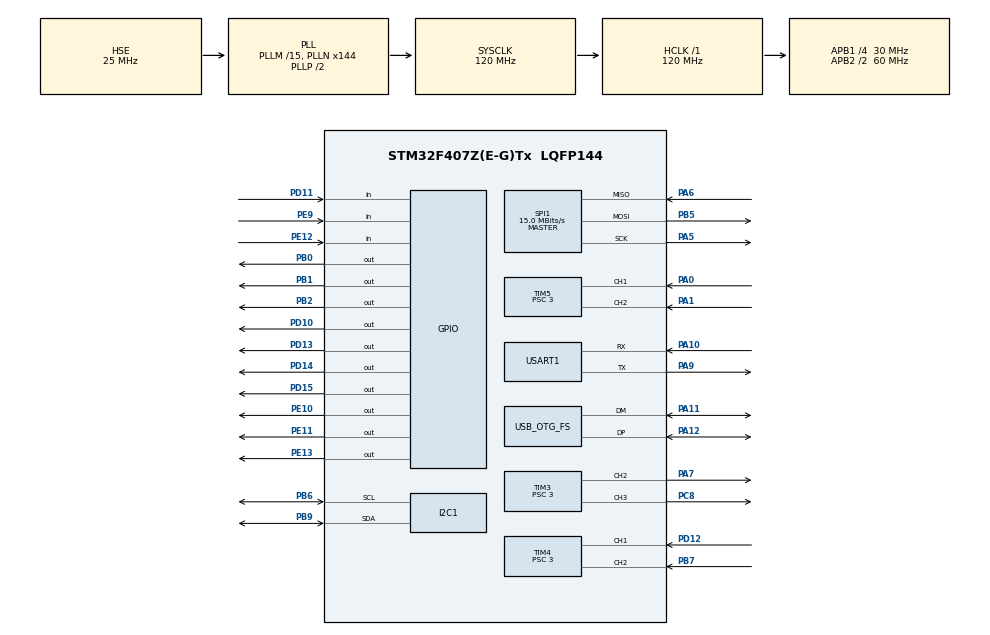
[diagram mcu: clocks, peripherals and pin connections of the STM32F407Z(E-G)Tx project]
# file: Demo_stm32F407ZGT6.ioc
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FREERTOS.MEMORY_ALLOCATION=2
FREERTOS.Tasks01=defaultTask,0,2000,StartDefaultTask,Default,NULL,Dynamic,NULL,NULL
FREERTOS.configMINIMAL_STACK_SIZE=2000
FREERTOS.configTICK_RATE_HZ=100
FREERTOS.configTOTAL_HEAP_SIZE=55360
Mcu.Family=STM32F4
Mcu.Name=STM32F407Z(E-G)Tx
Mcu.Package=LQFP144
NVIC.OTG_FS_IRQn=true\:5\:0\:false\:false\:true\:true\:false\:true
NVIC.PriorityGroup=NVIC_PRIORITYGROUP_4
NVIC.TIM1_UP_TIM10_IRQn=true\:0\:0\:false\:false\:true\:false\:false\:true
NVIC.TIM2_IRQn=true\:5\:0\:false\:false\:true\:true\:true\:true
NVIC.TimeBase=TIM1_UP_TIM10_IRQn
NVIC.TimeBaseIP=TIM1
PA0-WKUP.Signal=S_TIM5_CH1
PA1.Signal=S_TIM5_CH2
PA10.Mode=Asynchronous
PA10.Signal=USART1_RX
PA11.Mode=Device_Only
PA11.Signal=USB_OTG_FS_DM
PA12.Mode=Device_Only
PA12.Signal=USB_OTG_FS_DP
PA5.Mode=Full_Duplex_Master
PA5.Signal=SPI1_SCK
PA6.Mode=Full_Duplex_Master
PA6.Signal=SPI1_MISO
PA7.Signal=S_TIM3_CH2
PA9.Mode=Asynchronous
PA9.Signal=USART1_TX
PB0.Signal=GPIO_Output
PB1.Signal=GPIO_Output
PB2.Signal=GPIO_Output
PB5.Mode=Full_Duplex_Master
PB5.Signal=SPI1_MOSI
PB6.Mode=I2C
PB6.Signal=I2C1_SCL
PB7.Signal=S_TIM4_CH2
PB9.Mode=I2C
PB9.Signal=I2C1_SDA
PC8.Signal=S_TIM3_CH3
PD10.Signal=GPIO_Output
PD11.Signal=GPIO_Input
PD12.Signal=S_TIM4_CH1
PD13.Signal=GPIO_Output
PD14.Signal=GPIO_Output
PD15.Signal=GPIO_Output
PE10.Signal=GPIO_Output
PE11.Signal=GPIO_Output
PE12.Signal=GPIO_Input
PE13.Signal=GPIO_Output
PE9.Signal=GPIO_Input
PH0-OSC_IN.Mode=HSE-External-Oscillator
PH0-OSC_IN.Signal=RCC_OSC_IN
PH1-OSC_OUT.Mode=HSE-External-Oscillator
PH1-OSC_OUT.Signal=RCC_OSC_OUT
ProjectManager.HeapSize=0x200
ProjectManager.StackSize=0x400
ProjectManager.TargetToolchain=STM32CubeIDE
RCC.48MHZClocksFreq_Value=48000000
RCC.AHBFreq_Value=120000000
RCC.APB1CLKDivider=RCC_HCLK_DIV4
RCC.APB1Freq_Value=30000000
RCC.APB1TimFreq_Value=60000000
RCC.APB2CLKDivider=RCC_HCLK_DIV2
RCC.APB2Freq_Value=60000000
RCC.APB2TimFreq_Value=120000000
RCC.CortexFreq_Value=120000000
RCC.HCLKFreq_Value=120000000
RCC.HSE_VALUE=25000000
RCC.HSI_VALUE=16000000
RCC.LSE_VALUE=32768
RCC.PLLM=15
RCC.PLLN=144
RCC.PLLQ=5
RCC.SYSCLKFreq_VALUE=120000000
RCC.SYSCLKSource=RCC_SYSCLKSOURCE_PLLCLK
RCC.VCOOutputFreq_Value=240000000
SH.S_TIM3_CH2.0=TIM3_CH2,PWM Generation2 CH2
SH.S_TIM3_CH3.0=TIM3_CH3,PWM Generation3 CH3
SH.S_TIM4_CH1.0=TIM4_CH1,Encoder_Interface
SH.S_TIM4_CH2.0=TIM4_CH2,Encoder_Interface
SH.S_TIM5_CH1.0=TIM5_CH1,Encoder_Interface
SH.S_TIM5_CH2.0=TIM5_CH2,Encoder_Interface
SPI1.BaudRatePrescaler=SPI_BAUDRATEPRESCALER_4
SPI1.CalculateBaudRate=15.0 MBits/s
SPI1.Direction=SPI_DIRECTION_2LINES
SPI1.Mode=SPI_MODE_MASTER
SPI1.VirtualType=VM_MASTER
TIM2.AutoReloadPreload=TIM_AUTORELOAD_PRELOAD_ENABLE
TIM2.Period=83
TIM2.Prescaler=999
TIM3.AutoReloadPreload=TIM_AUTORELOAD_PRELOAD_ENABLE
TIM3.Channel-PWM\ Generation2\ CH2=TIM_CHANNEL_2
TIM3.Channel-PWM\ Generation3\ CH3=TIM_CHANNEL_3
TIM3.Period=2099
TIM3.Prescaler=3
TIM4.EncoderMode=TIM_ENCODERMODE_TI12
TIM4.Period=0xffff
TIM4.Prescaler=3
TIM5.EncoderMode=TIM_ENCODERMODE_TI12
TIM5.Period=0xffff
TIM5.Prescaler=3
USART1.VirtualMode=VM_ASYNC
USB_DEVICE.CLASS_NAME_FS=DFU
USB_DEVICE.VirtualMode-DFU_FS=Dfu
USB_DEVICE.VirtualModeFS=Dfu_FS
USB_OTG_FS.VirtualMode=Device_Only
VP_FREERTOS_VS_CMSIS_V1.Mode=CMSIS_V1
VP_SYS_VS_tim1.Mode=TIM1
VP_TIM2_VS_ClockSourceINT.Mode=Internal
VP_TIM3_VS_ClockSourceINT.Mode=Internal
VP_USB_DEVICE_VS_USB_DEVICE_DFU_FS.Mode=DFU_FS
board=custom

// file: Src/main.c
/* USER CODE BEGIN Header */
/**
  ******************************************************************************
  * @file           : main.c
  * @brief          : Main program body
  ******************************************************************************
  * @attention
  *
  * <h2><center>&copy; Copyright (c) 2020 STMicroelectronics.
  * All rights reserved.</center></h2>
  *
  * This software component is licensed by ST under Ultimate Liberty license
  * SLA0044, the "License"; You may not use this file except in compliance with
  * the License. You may obtain a copy of the License at:
  *                             www.st.com/SLA0044
  *
  ******************************************************************************
  */
/* USER CODE END Header */

#include "main.h"
#include "cmsis_os.h"
#include "usb_device.h"

/* USER CODE BEGIN Includes */
#include "pa_Main/pa_Main.h"
/* USER CODE END Includes */

I2C_HandleTypeDef hi2c1;

SPI_HandleTypeDef hspi1;

TIM_HandleTypeDef htim2;
TIM_HandleTypeDef htim3;
TIM_HandleTypeDef htim4;
TIM_HandleTypeDef htim5;

UART_HandleTypeDef huart1;

osThreadId defaultTaskHandle;

void SystemClock_Config(void);
static void MX_GPIO_Init(void);
static void MX_I2C1_Init(void);
static void MX_SPI1_Init(void);
static void MX_TIM2_Init(void);
static void MX_TIM3_Init(void);
static void MX_TIM4_Init(void);
static void MX_TIM5_Init(void);
static void MX_USART1_UART_Init(void);
void StartDefaultTask(void const * argument);

int main(void)
{

  /* MCU Configuration--------------------------------------------------------*/

  /* Reset of all peripherals, Initializes the Flash interface and the Systick. */
  HAL_Init();

  /* Configure the system clock */
  SystemClock_Config();

  /* Initialize all configured peripherals */
  MX_GPIO_Init();
  MX_I2C1_Init();
  MX_SPI1_Init();
  MX_TIM2_Init();
  MX_TIM3_Init();
  MX_TIM4_Init();
  MX_TIM5_Init();
  MX_USART1_UART_Init();

  /* Create the thread(s) */
  /* definition and creation of defaultTask */
  osThreadDef(defaultTask, StartDefaultTask, osPriorityNormal, 0, 2000);
  defaultTaskHandle = osThreadCreate(osThread(defaultTask), NULL);

  /* Start scheduler */
  osKernelStart();

  /* We should never get here as control is now taken by the scheduler */

  /* Infinite loop */
  while (1)
  {

  }
}

void SystemClock_Config(void)
{
  RCC_OscInitTypeDef RCC_OscInitStruct = {0};
  RCC_ClkInitTypeDef RCC_ClkInitStruct = {0};

  /** Configure the main internal regulator output voltage
  */
  __HAL_RCC_PWR_CLK_ENABLE();
  __HAL_PWR_VOLTAGESCALING_CONFIG(PWR_REGULATOR_VOLTAGE_SCALE1);
  /** Initializes the CPU, AHB and APB busses clocks
  */
  RCC_OscInitStruct.OscillatorType = RCC_OSCILLATORTYPE_HSE;
  RCC_OscInitStruct.HSEState = RCC_HSE_ON;
  RCC_OscInitStruct.PLL.PLLState = RCC_PLL_ON;
  RCC_OscInitStruct.PLL.PLLSource = RCC_PLLSOURCE_HSE;
  RCC_OscInitStruct.PLL.PLLM = 15;
  RCC_OscInitStruct.PLL.PLLN = 144;
  RCC_OscInitStruct.PLL.PLLP = RCC_PLLP_DIV2;
  RCC_OscInitStruct.PLL.PLLQ = 5;
  if (HAL_RCC_OscConfig(&RCC_OscInitStruct) != HAL_OK)
  {
    Error_Handler();
  }
  /** Initializes the CPU, AHB and APB busses clocks
  */
  RCC_ClkInitStruct.ClockType = RCC_CLOCKTYPE_HCLK|RCC_CLOCKTYPE_SYSCLK
                              |RCC_CLOCKTYPE_PCLK1|RCC_CLOCKTYPE_PCLK2;
  RCC_ClkInitStruct.SYSCLKSource = RCC_SYSCLKSOURCE_PLLCLK;
  RCC_ClkInitStruct.AHBCLKDivider = RCC_SYSCLK_DIV1;
  RCC_ClkInitStruct.APB1CLKDivider = RCC_HCLK_DIV4;
  RCC_ClkInitStruct.APB2CLKDivider = RCC_HCLK_DIV2;

  if (HAL_RCC_ClockConfig(&RCC_ClkInitStruct, FLASH_LATENCY_3) != HAL_OK)
  {
    Error_Handler();
  }
}

static void MX_I2C1_Init(void)
{

  hi2c1.Instance = I2C1;
  hi2c1.Init.ClockSpeed = 100000;
  hi2c1.Init.DutyCycle = I2C_DUTYCYCLE_2;
  hi2c1.Init.OwnAddress1 = 0;
  hi2c1.Init.AddressingMode = I2C_ADDRESSINGMODE_7BIT;
  hi2c1.Init.DualAddressMode = I2C_DUALADDRESS_DISABLE;
  hi2c1.Init.OwnAddress2 = 0;
  hi2c1.Init.GeneralCallMode = I2C_GENERALCALL_DISABLE;
  hi2c1.Init.NoStretchMode = I2C_NOSTRETCH_DISABLE;
  if (HAL_I2C_Init(&hi2c1) != HAL_OK)
  {
    Error_Handler();
  }

}

static void MX_SPI1_Init(void)
{

  /* SPI1 parameter configuration*/
  hspi1.Instance = SPI1;
  hspi1.Init.Mode = SPI_MODE_MASTER;
  hspi1.Init.Direction = SPI_DIRECTION_2LINES;
  hspi1.Init.DataSize = SPI_DATASIZE_8BIT;
  hspi1.Init.CLKPolarity = SPI_POLARITY_LOW;
  hspi1.Init.CLKPhase = SPI_PHASE_1EDGE;
  hspi1.Init.NSS = SPI_NSS_SOFT;
  hspi1.Init.BaudRatePrescaler = SPI_BAUDRATEPRESCALER_4;
  hspi1.Init.FirstBit = SPI_FIRSTBIT_MSB;
  hspi1.Init.TIMode = SPI_TIMODE_DISABLE;
  hspi1.Init.CRCCalculation = SPI_CRCCALCULATION_DISABLE;
  hspi1.Init.CRCPolynomial = 10;
  if (HAL_SPI_Init(&hspi1) != HAL_OK)
  {
    Error_Handler();
  }

}

static void MX_TIM2_Init(void)
{

  TIM_ClockConfigTypeDef sClockSourceConfig = {0};
  TIM_MasterConfigTypeDef sMasterConfig = {0};

  htim2.Instance = TIM2;
  htim2.Init.Prescaler = 999;
  htim2.Init.CounterMode = TIM_COUNTERMODE_UP;
  htim2.Init.Period = 83;
  htim2.Init.ClockDivision = TIM_CLOCKDIVISION_DIV1;
  htim2.Init.AutoReloadPreload = TIM_AUTORELOAD_PRELOAD_ENABLE;
  if (HAL_TIM_Base_Init(&htim2) != HAL_OK)
  {
    Error_Handler();
  }
  sClockSourceConfig.ClockSource = TIM_CLOCKSOURCE_INTERNAL;
  if (HAL_TIM_ConfigClockSource(&htim2, &sClockSourceConfig) != HAL_OK)
  {
    Error_Handler();
  }
  sMasterConfig.MasterOutputTrigger = TIM_TRGO_RESET;
  sMasterConfig.MasterSlaveMode = TIM_MASTERSLAVEMODE_DISABLE;
  if (HAL_TIMEx_MasterConfigSynchronization(&htim2, &sMasterConfig) != HAL_OK)
  {
    Error_Handler();
  }

}

static void MX_TIM3_Init(void)
{

  TIM_ClockConfigTypeDef sClockSourceConfig = {0};
  TIM_MasterConfigTypeDef sMasterConfig = {0};
  TIM_OC_InitTypeDef sConfigOC = {0};

  htim3.Instance = TIM3;
  htim3.Init.Prescaler = 3;
  htim3.Init.CounterMode = TIM_COUNTERMODE_UP;
  htim3.Init.Period = 2099;
  htim3.Init.ClockDivision = TIM_CLOCKDIVISION_DIV1;
  htim3.Init.AutoReloadPreload = TIM_AUTORELOAD_PRELOAD_ENABLE;
  if (HAL_TIM_Base_Init(&htim3) != HAL_OK)
  {
    Error_Handler();
  }
  sClockSourceConfig.ClockSource = TIM_CLOCKSOURCE_INTERNAL;
  if (HAL_TIM_ConfigClockSource(&htim3, &sClockSourceConfig) != HAL_OK)
  {
    Error_Handler();
  }
  if (HAL_TIM_PWM_Init(&htim3) != HAL_OK)
  {
    Error_Handler();
  }
  sMasterConfig.MasterOutputTrigger = TIM_TRGO_RESET;
  sMasterConfig.MasterSlaveMode = TIM_MASTERSLAVEMODE_DISABLE;
  if (HAL_TIMEx_MasterConfigSynchronization(&htim3, &sMasterConfig) != HAL_OK)
  {
    Error_Handler();
  }
  sConfigOC.OCMode = TIM_OCMODE_PWM1;
  sConfigOC.Pulse = 0;
  sConfigOC.OCPolarity = TIM_OCPOLARITY_HIGH;
  sConfigOC.OCFastMode = TIM_OCFAST_DISABLE;
  if (HAL_TIM_PWM_ConfigChannel(&htim3, &sConfigOC, TIM_CHANNEL_2) != HAL_OK)
  {
    Error_Handler();
  }
  if (HAL_TIM_PWM_ConfigChannel(&htim3, &sConfigOC, TIM_CHANNEL_3) != HAL_OK)
  {
    Error_Handler();
  }
  HAL_TIM_MspPostInit(&htim3);

}

static void MX_TIM4_Init(void)
{

  TIM_Encoder_InitTypeDef sConfig = {0};
  TIM_MasterConfigTypeDef sMasterConfig = {0};

  htim4.Instance = TIM4;
  htim4.Init.Prescaler = 3;
  htim4.Init.CounterMode = TIM_COUNTERMODE_UP;
  htim4.Init.Period = 0xffff;
  htim4.Init.ClockDivision = TIM_CLOCKDIVISION_DIV1;
  htim4.Init.AutoReloadPreload = TIM_AUTORELOAD_PRELOAD_DISABLE;
  sConfig.EncoderMode = TIM_ENCODERMODE_TI12;
  sConfig.IC1Polarity = TIM_ICPOLARITY_RISING;
  sConfig.IC1Selection = TIM_ICSELECTION_DIRECTTI;
  sConfig.IC1Prescaler = TIM_ICPSC_DIV1;
  sConfig.IC1Filter = 0;
  sConfig.IC2Polarity = TIM_ICPOLARITY_RISING;
  sConfig.IC2Selection = TIM_ICSELECTION_DIRECTTI;
  sConfig.IC2Prescaler = TIM_ICPSC_DIV1;
  sConfig.IC2Filter = 0;
  if (HAL_TIM_Encoder_Init(&htim4, &sConfig) != HAL_OK)
  {
    Error_Handler();
  }
  sMasterConfig.MasterOutputTrigger = TIM_TRGO_RESET;
  sMasterConfig.MasterSlaveMode = TIM_MASTERSLAVEMODE_DISABLE;
  if (HAL_TIMEx_MasterConfigSynchronization(&htim4, &sMasterConfig) != HAL_OK)
  {
    Error_Handler();
  }

}

static void MX_TIM5_Init(void)
{

  TIM_Encoder_InitTypeDef sConfig = {0};
  TIM_MasterConfigTypeDef sMasterConfig = {0};

  htim5.Instance = TIM5;
  htim5.Init.Prescaler = 3;
  htim5.Init.CounterMode = TIM_COUNTERMODE_UP;
  htim5.Init.Period = 0xffff;
  htim5.Init.ClockDivision = TIM_CLOCKDIVISION_DIV1;
  htim5.Init.AutoReloadPreload = TIM_AUTORELOAD_PRELOAD_DISABLE;
  sConfig.EncoderMode = TIM_ENCODERMODE_TI12;
  sConfig.IC1Polarity = TIM_ICPOLARITY_RISING;
  sConfig.IC1Selection = TIM_ICSELECTION_DIRECTTI;
  sConfig.IC1Prescaler = TIM_ICPSC_DIV1;
  sConfig.IC1Filter = 0;
  sConfig.IC2Polarity = TIM_ICPOLARITY_RISING;
  sConfig.IC2Selection = TIM_ICSELECTION_DIRECTTI;
  sConfig.IC2Prescaler = TIM_ICPSC_DIV1;
  sConfig.IC2Filter = 0;
  if (HAL_TIM_Encoder_Init(&htim5, &sConfig) != HAL_OK)
  {
    Error_Handler();
  }
  sMasterConfig.MasterOutputTrigger = TIM_TRGO_RESET;
  sMasterConfig.MasterSlaveMode = TIM_MASTERSLAVEMODE_DISABLE;
  if (HAL_TIMEx_MasterConfigSynchronization(&htim5, &sMasterConfig) != HAL_OK)
  {
    Error_Handler();
  }

}

static void MX_USART1_UART_Init(void)
{

  huart1.Instance = USART1;
  huart1.Init.BaudRate = 115200;
  huart1.Init.WordLength = UART_WORDLENGTH_8B;
  huart1.Init.StopBits = UART_STOPBITS_1;
  huart1.Init.Parity = UART_PARITY_NONE;
  huart1.Init.Mode = UART_MODE_TX_RX;
  huart1.Init.HwFlowCtl = UART_HWCONTROL_NONE;
  huart1.Init.OverSampling = UART_OVERSAMPLING_16;
  if (HAL_UART_Init(&huart1) != HAL_OK)
  {
    Error_Handler();
  }

}

static void MX_GPIO_Init(void)
{
  GPIO_InitTypeDef GPIO_InitStruct = {0};

  /* GPIO Ports Clock Enable */
  __HAL_RCC_GPIOH_CLK_ENABLE();
  __HAL_RCC_GPIOA_CLK_ENABLE();
  __HAL_RCC_GPIOB_CLK_ENABLE();
  __HAL_RCC_GPIOE_CLK_ENABLE();
  __HAL_RCC_GPIOD_CLK_ENABLE();
  __HAL_RCC_GPIOC_CLK_ENABLE();

  /*Configure GPIO pin Output Level */
  HAL_GPIO_WritePin(GPIOB, GPIO_PIN_0|GPIO_PIN_1|GPIO_PIN_2, GPIO_PIN_RESET);

  /*Configure GPIO pin Output Level */
  HAL_GPIO_WritePin(GPIOE, GPIO_PIN_10|GPIO_PIN_11|GPIO_PIN_13, GPIO_PIN_RESET);

  /*Configure GPIO pin Output Level */
  HAL_GPIO_WritePin(GPIOD, GPIO_PIN_10|GPIO_PIN_13|GPIO_PIN_14|GPIO_PIN_15, GPIO_PIN_RESET);

  /*Configure GPIO pins : PB0 PB1 PB2 */
  GPIO_InitStruct.Pin = GPIO_PIN_0|GPIO_PIN_1|GPIO_PIN_2;
  GPIO_InitStruct.Mode = GPIO_MODE_OUTPUT_PP;
  GPIO_InitStruct.Pull = GPIO_NOPULL;
  GPIO_InitStruct.Speed = GPIO_SPEED_FREQ_LOW;
  HAL_GPIO_Init(GPIOB, &GPIO_InitStruct);

  /*Configure GPIO pins : PE9 PE12 */
  GPIO_InitStruct.Pin = GPIO_PIN_9|GPIO_PIN_12;
  GPIO_InitStruct.Mode = GPIO_MODE_INPUT;
  GPIO_InitStruct.Pull = GPIO_NOPULL;
  HAL_GPIO_Init(GPIOE, &GPIO_InitStruct);

  /*Configure GPIO pins : PE10 PE11 PE13 */
  GPIO_InitStruct.Pin = GPIO_PIN_10|GPIO_PIN_11|GPIO_PIN_13;
  GPIO_InitStruct.Mode = GPIO_MODE_OUTPUT_PP;
  GPIO_InitStruct.Pull = GPIO_NOPULL;
  GPIO_InitStruct.Speed = GPIO_SPEED_FREQ_LOW;
  HAL_GPIO_Init(GPIOE, &GPIO_InitStruct);

  /*Configure GPIO pins : PD10 PD13 PD14 PD15 */
  GPIO_InitStruct.Pin = GPIO_PIN_10|GPIO_PIN_13|GPIO_PIN_14|GPIO_PIN_15;
  GPIO_InitStruct.Mode = GPIO_MODE_OUTPUT_PP;
  GPIO_InitStruct.Pull = GPIO_NOPULL;
  GPIO_InitStruct.Speed = GPIO_SPEED_FREQ_LOW;
  HAL_GPIO_Init(GPIOD, &GPIO_InitStruct);

  /*Configure GPIO pin : PD11 */
  GPIO_InitStruct.Pin = GPIO_PIN_11;
  GPIO_InitStruct.Mode = GPIO_MODE_INPUT;
  GPIO_InitStruct.Pull = GPIO_NOPULL;
  HAL_GPIO_Init(GPIOD, &GPIO_InitStruct);

}

void StartDefaultTask(void const * argument)
{
  /* init code for USB_DEVICE */
  MX_USB_DEVICE_Init();

  /* USER CODE BEGIN 5 */
  /* Infinite loop */
  pa_Main();
  for(;;)
  {
    osDelay(1);
  }
  /* USER CODE END 5 */
}

void HAL_TIM_PeriodElapsedCallback(TIM_HandleTypeDef *htim)
{
  /* USER CODE BEGIN Callback 0 */
  if (htim->Instance == TIM2) {
    tim_1ms_tick();
  }
  /* USER CODE END Callback 0 */
  if (htim->Instance == TIM1) {
    HAL_IncTick();
  }
}

void Error_Handler(void)
{
}

/************************ (C) COPYRIGHT STMicroelectronics *****END OF FILE****/
